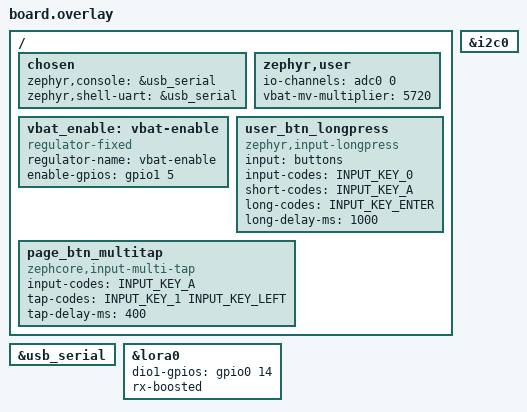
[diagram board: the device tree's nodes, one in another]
/*
 * SPDX-License-Identifier: MIT
 * Heltec WiFi LoRa 32 V4.3 — ZephCore overlay
 *
 * The DTS already defines: SX1262 (lora0), SSD1306 OLED, button, LED, PWM,
 * vext_enable, fem_power, I2C0, SPI2, BLE, WiFi.
 * This overlay adds ZephCore-specific integration on top.
 *
 * LoRa SPI2:  SCLK=9, MOSI=10, MISO=11, NSS=8
 * LoRa ctrl:  DIO1=14, BUSY=13, RESET=12
 * FEM:        POWER=7, KCT8103L CSD=2, CTX=5
 * Display I2C0: SDA=17, SCL=18, RST=21
 * Battery ADC: GPIO1 = ADC1_CH0 (&adc0), enable GPIO37 active-HIGH, divider 100K/390K
 * Vext:       GPIO36 (active-HIGH, powers OLED)
 * Button:     GPIO0
 * LED:        GPIO35
 */

#include <zephyr/dt-bindings/input/input-event-codes.h>

/ {
	chosen {
		/* Native USB serial for ZephCore console/CLI */
		zephyr,console = &usb_serial;
		zephyr,shell-uart = &usb_serial;
	};

	/* Battery ADC — ZephCore reads via zephyr,user { io-channels }.
	 * GPIO1 = ADC unit 1 = node &adc0 (label is 0-indexed, unit is 1-indexed);
	 * the old &adc1 was unit 2 = GPIO11 = SX1262 MISO — always read 0.
	 * Multiplier: Vref_internal(1100) * divider_ratio(5.2) = 5720 on the
	 * 100K/390K divider (was 17886, which assumed a 3300mV full-scale that
	 * ADC_REF_INTERNAL does not provide). Channel config is in the DTS. */
	zephyr,user {
		io-channels = <&adc0 0>;
		vbat-mv-multiplier = <5720>;
	};

	/* Battery ADC enable — ZephCore uses vbat_enable regulator alias.
	 * GPIO37 (gpio1 pin 5) driven HIGH enables the ADC input path. ZephyrBoard
	 * toggles this per read (enable, sample, disable), so the divider draws
	 * nothing between reads. The DTS no longer defines an adc_ctrl power-domain
	 * on the same GPIO37, so this regulator is the sole owner. */
	vbat_enable: vbat-enable {
		compatible = "regulator-fixed";
		regulator-name = "vbat-enable";
		enable-gpios = <&gpio1 5 GPIO_ACTIVE_HIGH>;  /* GPIO37 = gpio1 pin 5, HIGH enables (V4/V4.3) */
	};

	/* Button chain — same mapping as RAK4631 / WisMesh Pocket (rak4631/board.overlay). */
	user_btn_longpress {
		compatible = "zephyr,input-longpress";
		input = <&buttons>;
		input-codes = <INPUT_KEY_0>;
		short-codes = <INPUT_KEY_A>;
		long-codes = <INPUT_KEY_ENTER>;
		long-delay-ms = <1000>;
	};

	page_btn_multitap {
		compatible = "zephcore,input-multi-tap";
		input-codes = <INPUT_KEY_A>;
		tap-codes = <INPUT_KEY_1 INPUT_KEY_LEFT>;
		tap-delay-ms = <400>;
	};
};

/* Enable native USB serial for console/CLI */
&usb_serial {
	status = "okay";
};

/* Patch LoRa radio: add pull-down on DIO1 and enable RX boosted mode.
 * DTS defines antenna-enable, tx-enable, dio2-tx-enable, and TCXO already. */
&lora0 {
	dio1-gpios = <&gpio0 14 (GPIO_PULL_DOWN | GPIO_ACTIVE_HIGH)>;
	rx-boosted;
};

/* I2C sensors — auto-detected at runtime */
&i2c0 {
	#include "../../common/sensors-i2c.dtsi"
};

/*
 * Flash partitions live in partitions.overlay (this dir) so the identical map
 * is fed to both the app and the MCUboot image — see that file and
 * sysbuild/CMakeLists.txt.
 */

/* LittleFS auto-mount — standard /lfs mount point */
#include "../../common/filesystem.dtsi"
/* USB CDC-ACM — companion USB transport (esp32s3_usb.conf). Heltec has a
 * dedicated UART console, so no console reroute is needed. */
#include "../../common/esp32s3_usb_otg.dtsi"
